# STM32H573 register map
File version: 1.8
CPU: CM33 r0p0, little endian, MPU, FPU, 4 interrupt priority bits
Registers are 32-bit, read-write, reset 0x0 unless marked. A register's access mark holds for its fields unless they carry their own. Offsets are from the block's base; [hi:lo] are bit positions; 'fields as' and 'values as' point back to an identical list.

## UCPD1 — USB Power Delivery interface
Base 0x4000DC00
Same registers: SEC_UCPD1 0x5000DC00
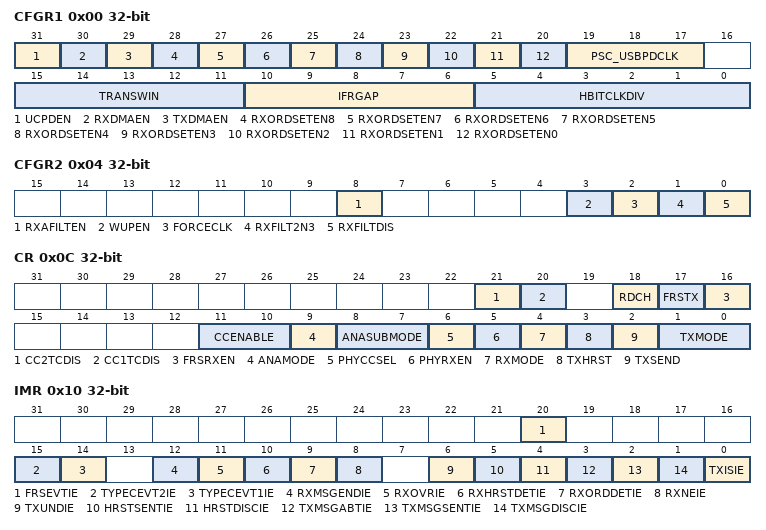
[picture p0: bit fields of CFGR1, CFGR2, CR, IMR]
0x00 CFGR1 access not given — UCPD configuration register 1
  [31] UCPDEN rw — UCPD peripheral enable General enable of the UCPD peripheral. Upon disabling, the peripheral instantly quits any ongoing activity and all control bits and bitfields default to their reset values. They must be set to their desired values each time the peripheral transits from disabled to enabled state.
    0=Disabled (UCPD peripheral disabled); 1=Enabled (UCPD peripheral enabled)
  [30] RXDMAEN rw — Reception DMA mode enable When set, the bit enables DMA mode for reception.
    0=Disabled (DMA mode for reception disabled); 1=Enabled (DMA mode for reception enabled)
  [29] TXDMAEN rw — Transmission DMA mode enable When set, the bit enables DMA mode for transmission.
    0=Disabled (DMA mode for transmission disabled); 1=Enabled (DMA mode for transmission enabled)
  [28] RXORDSETEN8 — SOP extension #2
    0=Disabled (Flag disabled); 1=Enabled (Flag enabled)
  [27] RXORDSETEN7 — SOP extension #1
    0=Disabled (Flag disabled); 1=Enabled (Flag enabled)
  [26] RXORDSETEN6 — SOP'' Debug
    0=Disabled (Flag disabled); 1=Enabled (Flag enabled)
  [25] RXORDSETEN5 — SOP'_Debug
    0=Disabled (Flag disabled); 1=Enabled (Flag enabled)
  [24] RXORDSETEN4 — Cable Detect reset
    0=Disabled (Flag disabled); 1=Enabled (Flag enabled)
  [23] RXORDSETEN3 — Hard Reset detection
    0=Disabled (Flag disabled); 1=Enabled (Flag enabled)
  [22] RXORDSETEN2 — SOP'' detection
    0=Disabled (Flag disabled); 1=Enabled (Flag enabled)
  [21] RXORDSETEN1 — SOP' detection
    0=Disabled (Flag disabled); 1=Enabled (Flag enabled)
  [20] RXORDSETEN0 — SOP detection
    0=Disabled (Flag disabled); 1=Enabled (Flag enabled)
  [19:17] PSC_USBPDCLK rw — Pre-scaler division ratio for generating ucpd_clk The bitfield determines the division ratio of a kernel clock pre-scaler producing UCPD peripheral clock (ucpd_clk). It is recommended to use the pre-scaler so as to set the ucpd_clk frequency in the range from 6 to 9 MHz.
    0=Div1 (Divide by 1); 1=Div2 (Divide by 2); 2=Div4 (Divide by 4); 3=Div8 (Divide by 8); 4=Div16 (Divide by 16)
  [15:11] TRANSWIN rw range 1..31 — Transition window duration The bitfield determines the division ratio (the bitfield value minus one) of a hbit_clk divider producing tTransitionWindow interval. Set a value that produces an interval of 12 to 20 us, taking into account the ucpd_clk frequency and the HBITCLKDIV[5:0] bitfield setting.
  [10:6] IFRGAP rw range 1..31 — Division ratio for producing inter-frame gap timer clock The bitfield determines the division ratio (the bitfield value minus one) of a ucpd_clk divider producing inter-frame gap timer clock (tInterFrameGap). The division ratio 15 is to apply for Tx clock at the USB PD 2.0 specification nominal value. The division ratios below 15 are to apply for Tx clock below nominal, and the division ratios above 15 for Tx clock above nominal.
  [5:0] HBITCLKDIV rw — Division ratio for producing half-bit clock The bitfield determines the division ratio (the bitfield value plus one) of a ucpd_clk divider producing half-bit clock (hbit_clk).
0x04 CFGR2 — UCPD configuration register 2
  [8] RXAFILTEN — Rx analog filter enable Setting the bit enables the Rx analog filter required for optimum Power Delivery reception.
    0=Disabled; 1=Enabled
  [3] WUPEN — Wakeup from Stop mode enable Setting the bit enables the UCPD_ASYNC_INT signal.
    0=Disabled; 1=Enabled
  [2] FORCECLK — Force ClkReq clock request
    0=NoForce (Do not force clock request); 1=Force clock request
  [1] RXFILT2N3 — BMC decoder Rx pre-filter sampling method Number of consistent consecutive samples before confirming a new value.
    0=Samp3 (3 samples); 1=Samp2 (2 samples)
  [0] RXFILTDIS — BMC decoder Rx pre-filter enable The sampling clock is that of the receiver (that is, after pre-scaler).
    0=Enabled (Rx pre-filter enabled); 1=Disabled (Rx pre-filter disabled)
0x0C CR — UCPD control register
  [21] CC2TCDIS — CC2 Type-C detector disable The bit disables the Type-C detector on the CC2 line. When enabled, the Type-C detector for CC2 is configured through ANAMODE and ANASUBMODE[1:0].
    0=Enabled (Type-C detector on the CCx line enabled); 1=Disabled (Type-C detector on the CCx line disabled)
  [20] CC1TCDIS — CC1 Type-C detector disable The bit disables the Type-C detector on the CC1 line. When enabled, the Type-C detector for CC1 is configured through ANAMODE and ANASUBMODE[1:0].
    values as CC2TCDIS
  [18] RDCH — Rdch condition drive The bit drives Rdch condition on the CC line selected through the PHYCCSEL bit (thus associated with VCONN), by remaining set during the source-only UnattachedWait.SRC state, to respect the Type-C state. Refer to 'USB Type-C ECN for Source VCONN Discharge'. The CCENABLE[1:0] bitfield must be set accordingly, too.
    0=NoEffect; 1=ConditionDrive (Rdch condition drive)
  [17] FRSTX — FRS Tx signaling enable. Setting the bit enables FRS Tx signaling. The bit is cleared by hardware after a delay respecting the USB Power Delivery specification Revision 3.0.
    0=NoEffect; 1=Enabled (FRS Tx signaling enabled)
  [16] FRSRXEN — FRS event detection enable Setting the bit enables FRS Rx event (FRSEVT) detection on the CC line selected through the PHYCCSEL bit. 0: Disable Clear the bit when the device is attached to an FRS-incapable source/sink.
    0=Disabled (FRS Rx event detection disabled); 1=Enabled (FRS Rx event detection enabled)
  [11:10] CCENABLE — CC line enable This bitfield enables CC1 and CC2 line analog PHYs (pull-ups and pull-downs) according to ANAMODE and ANASUBMODE[1:0] setting. A single line PHY can be enabled when, for example, the other line is driven by VCONN via an external VCONN switch. Enabling both PHYs is the normal usage for sink/source.
    0=Disabled (Both PHYs disabled); 1=CC1Enabled (CC1 PHY enabled); 2=CC2Enabled (CC2 PHY enabled); 3=BothEnabled (CC1 and CC2 PHYs enabled)
  [9] ANAMODE — Analog PHY operating mode The use of CC1 and CC2 depends on CCENABLE. Refer to ANAMODE, ANASUBMODE and link with TYPEC_VSTATE_CCx for the effect of this bitfield in conjunction with ANASUBMODE[1:0].
    0=Source; 1=Sink
  [8:7] ANASUBMODE — Analog PHY sub-mode Refer to TYPEC_VSTATE_CCx for the effect of this bitfield.
    0=Disabled; 1=Rp_DefaultUSB (Default USB Rp); 2=Rp_1_5A (1.5A Rp); 3=Rp_3A (3A Rp)
  [6] PHYCCSEL — CC1/CC2 line selector for USB Power Delivery signaling The selection depends on the cable orientation as discovered at attach.
    0=CC1 (Use CC1 IO for Power Delivery communication); 1=CC2 (Use CC2 IO for Power Delivery communication)
  [5] PHYRXEN — USB Power Delivery receiver enable Both CC1 and CC2 receivers are disabled when the bit is cleared. Only the CC receiver selected via the PHYCCSEL bit is enabled when the bit is set.
    0=Disabled (USB Power Delivery receiver disabled); 1=Enabled (USB Power Delivery receiver enabled)
  [4] RXMODE — Receiver mode Determines the mode of the receiver. When the bit is set, RXORDSET behaves normally, RXDR no longer receives bytes yet the CRC checking still proceeds as for a normal message. As this mode prevents reception of the header (containing MessageID), software has to auto-increment a received MessageID counter for inclusion in the GoodCRC acknowledge that must still be transmitted during this test.
    0=Normal receive mode; 1=BIST (BIST receive mode (BIST test data mode))
  [3] TXHRST — Command to send a Tx Hard Reset The bit is cleared by hardware as soon as the message transmission begins or is discarded.
    0=NoEffect; 1=Start Tx Hard Reset message
  [2] TXSEND — Command to send a Tx packet The bit is cleared by hardware as soon as the packet transmission begins or is discarded.
    0=NoEffect; 1=Start Tx packet transmission
  [1:0] TXMODE — Type of Tx packet Writing the bitfield triggers the action as follows, depending on the value: Others: invalid From V1.1 of the USB PD specification, there is a counter defined for the duration of the BIST Carrier Mode 2. To quit this mode correctly (after the 'tBISTContMode' delay), disable the peripheral (UCPDEN = 0).
    0=RegisterSet (Transmission of Tx packet previously defined in other registers); 1=Cable Reset sequence; 2=BIST test sequence (BIST Carrier Mode 2)
0x10 IMR access per field — UCPD interrupt mask register
  [all] fields
    0=Disabled (Interrupt disabled); 1=Enabled (Interrupt enabled)
  [20] FRSEVTIE ro — FRSEVT interrupt enable
  [15] TYPECEVT2IE rw — TYPECEVT2 interrupt enable
  [14] TYPECEVT1IE rw — TYPECEVT1 interrupt enable
  [12] RXMSGENDIE rw — RXMSGEND interrupt enable
  [11] RXOVRIE rw — RXOVR interrupt enable
  [10] RXHRSTDETIE rw — RXHRSTDET interrupt enable
  [9] RXORDDETIE rw — RXORDDET interrupt enable
  [8] RXNEIE rw — RXNE interrupt enable
  [6] TXUNDIE rw — TXUND interrupt enable
  [5] HRSTSENTIE rw — HRSTSENT interrupt enable
  [4] HRSTDISCIE rw — HRSTDISC interrupt enable
  [3] TXMSGABTIE rw — TXMSGABT interrupt enable
  [2] TXMSGSENTIE rw — TXMSGSENT interrupt enable
  [1] TXMSGDISCIE rw — TXMSGDISC interrupt enable
  [0] TXISIE rw — TXIS interrupt enable
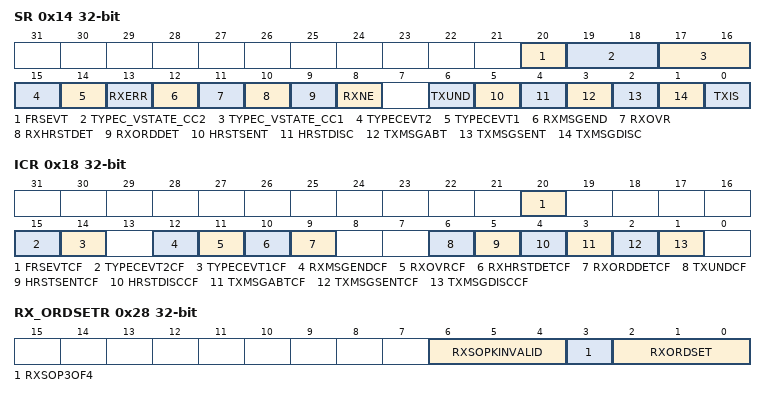
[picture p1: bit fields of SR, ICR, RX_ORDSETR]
0x14 SR ro — UCPD status register
  [20] FRSEVT — FRS detection event The flag is cleared by setting the FRSEVTCF bit.
    0=NoNewEvent; 1=NewEvent (New FRS receive event occurred)
  [19:18] TYPEC_VSTATE_CC2 — CC2 line voltage level The status bitfield indicates the voltage level on the CC2 line in its steady state. The voltage variation on the CC2 line during USB PD messages due to the BMC PHY modulation does not impact the bitfield value.
    0=Lowest; 1=Low; 2=High; 3=Highest
  [17:16] TYPEC_VSTATE_CC1 — The status bitfield indicates the voltage level on the CC1 line in its steady state. The voltage variation on the CC1 line during USB PD messages due to the BMC PHY modulation does not impact the bitfield value.
    0=Lowest; 1=Low; 2=High; 3=Highest
  [15] TYPECEVT2 — Type-C voltage level event on CC2 line The flag indicates a change of the TYPEC_VSTATE_CC2[1:0] bitfield value, which corresponds to a new Type-C event. It is cleared by setting the TYPECEVT2CF bit.
    0=NoNewEvent; 1=NewEvent (A new Type-C event occurred)
  [14] TYPECEVT1 — Type-C voltage level event on CC1 line The flag indicates a change of the TYPEC_VSTATE_CC1[1:0] bitfield value, which corresponds to a new Type-C event. It is cleared by setting the TYPECEVT2CF bit.
    0=NoNewEvent; 1=NewEvent (A new Type-C event occurred)
  [13] RXERR — Receive message error The flag indicates errors of the last Rx message declared (via RXMSGEND), such as incorrect CRC or truncated message (a line becoming static before EOP is met). It is asserted whenever the RXMSGEND flag is set.
    0=No error detected; 1=Error(s) detected
  [12] RXMSGEND — Rx message received The flag indicates whether a message (except Hard Reset message) has been received, regardless the CRC value. The flag is cleared by setting the RXMSGENDCF bit. The RXERR flag set when the RXMSGEND flag goes high indicates errors in the last-received message.
    0=NoNewMessage (No new Rx message received); 1=NewMessage (A new Rx message received)
  [11] RXOVR — Rx data overflow detection The flag indicates Rx data buffer overflow. It is cleared by setting the RXOVRCF bit. The buffer overflow can occur if the received data are not read fast enough.
    0=NoOverflow; 1=Overflow
  [10] RXHRSTDET — Rx Hard Reset receipt detection The flag indicates the receipt of valid Hard Reset message. It is cleared by setting the RXHRSTDETCF bit.
    0=NoHardReset (Hard Reset not received); 1=Hard Reset received
  [9] RXORDDET — Rx ordered set (4 K-codes) detection The flag indicates the detection of an ordered set. The relevant information is stored in the RXORDSET[2:0] bitfield of the UCPD_RX_ORDSET register. It is cleared by setting the RXORDDETCF bit.
    0=No ordered set detected; 1=Ordered set detected
  [8] RXNE — Receive data register not empty detection The flag indicates that the UCPD_RXDR register is not empty. It is automatically cleared upon reading UCPD_RXDR.
    0=Empty (Rx data register empty); 1=NotEmpty (Rx data register not empty)
  [6] TXUND — Tx data underrun detection The flag indicates that the Tx data register (UCPD_TXDR) was not written in time for a transmit message to execute normally. It is cleared by setting the TXUNDCF bit.
    0=NoUnderrun (No Tx data underrun detected); 1=Underrun (Tx data underrun detected)
  [5] HRSTSENT — Hard Reset message sent The flag indicates that the Hard Reset message is sent. The flag is cleared by setting the HRSTSENTCF bit.
    0=NotSent (No Hard Reset message sent); 1=Sent (Hard Reset message sent)
  [4] HRSTDISC — Hard Reset discarded The flag indicates that the Hard Reset message is discarded. The flag is cleared by setting the HRSTDISCCF bit.
    0=NotDiscarded (No Hard Reset discarded); 1=Discarded (Hard Reset discarded)
  [3] TXMSGABT — Transmit message abort The flag indicates that a Tx message is aborted due to a subsequent Hard Reset message send request taking priority during transmit. It is cleared by setting the TXMSGABTCF bit.
    0=NoAbort (No transmit message abort); 1=Abort (Transmit message abort)
  [2] TXMSGSENT — Message transmission completed The flag indicates the completion of packet transmission. It is cleared by setting the TXMSGSENTCF bit. In the event of a message transmission interrupted by a Hard Reset, the flag is not raised.
    0=NotCompleted (No Tx message completed); 1=Completed (Tx message completed)
  [1] TXMSGDISC — Message transmission discarded The flag indicates that a message transmission was dropped. The flag is cleared by setting the TXMSGDISCCF bit. Transmission of a message can be dropped if there is a concurrent receive in progress or at excessive noise on the line. After a Tx message is discarded, the flag is only raised when the CC line becomes idle.
    0=NotDiscarded (No Tx message discarded); 1=Discarded (Tx message discarded)
  [0] TXIS — Transmit interrupt status The flag indicates that the UCPD_TXDR register is empty and new data write is required (as the amount of data sent has not reached the payload size defined in the TXPAYSZ bitfield). The flag is cleared with the data write into the UCPD_TXDR register.
    0=NotRequired (New Tx data write not required); 1=Required (New Tx data write required)
0x18 ICR wo — UCPD interrupt clear register
  [all] fields
    1=Clear flag in UCPD_SR
  [20] FRSEVTCF — FRS event flag (FRSEVT) clear Setting the bit clears the FRSEVT flag in the UCPD_SR register.
  [15] TYPECEVT2CF — Type-C CC2 line event flag (TYPECEVT2) clear Setting the bit clears the TYPECEVT2 flag in the UCPD_SR register
  [14] TYPECEVT1CF — Type-C CC1 event flag (TYPECEVT1) clear Setting the bit clears the TYPECEVT1 flag in the UCPD_SR register
  [12] RXMSGENDCF — Rx message received flag (RXMSGEND) clear Setting the bit clears the RXMSGEND flag in the UCPD_SR register.
  [11] RXOVRCF — Rx overflow flag (RXOVR) clear Setting the bit clears the RXOVR flag in the UCPD_SR register.
  [10] RXHRSTDETCF — Rx Hard Reset detect flag (RXHRSTDET) clear Setting the bit clears the RXHRSTDET flag in the UCPD_SR register.
  [9] RXORDDETCF — Rx ordered set detect flag (RXORDDET) clear Setting the bit clears the RXORDDET flag in the UCPD_SR register.
  [6] TXUNDCF — Tx underflow flag (TXUND) clear Setting the bit clears the TXUND flag in the UCPD_SR register.
  [5] HRSTSENTCF — Hard reset send flag (HRSTSENT) clear Setting the bit clears the HRSTSENT flag in the UCPD_SR register.
  [4] HRSTDISCCF — Hard reset discard flag (HRSTDISC) clear Setting the bit clears the HRSTDISC flag in the UCPD_SR register.
  [3] TXMSGABTCF — Tx message abort flag (TXMSGABT) clear Setting the bit clears the TXMSGABT flag in the UCPD_SR register.
  [2] TXMSGSENTCF — Tx message send flag (TXMSGSENT) clear Setting the bit clears the TXMSGSENT flag in the UCPD_SR register.
  [1] TXMSGDISCCF — Tx message discard flag (TXMSGDISC) clear Setting the bit clears the TXMSGDISC flag in the UCPD_SR register.
0x1C TX_ORDSETR — UCPD Tx ordered set type register
  [19:0] TXORDSET — Ordered set to transmit The bitfield determines a full 20-bit sequence to transmit, consisting of four K-codes, each of five bits, defining the packet to transmit. The bit 0 (bit 0 of K-code1) is the first, the bit 19 (bit 4 of K code4) the last.
0x20 TX_PAYSZR — UCPD Tx payload size register
  [9:0] TXPAYSZ — Payload size yet to transmit The bitfield is modified by software and by hardware. It contains the number of bytes of a payload (including header but excluding CRC) yet to transmit: each time a data byte is written into the UCPD_TXDR register, the bitfield value decrements and the TXIS bit is set, except when the bitfield value reaches zero. The enumerated values are standard payload sizes before the start of transmission.
0x24 TXDR — UCPD Tx data register
  [7:0] TXDATA — Data byte to transmit
0x28 RX_ORDSETR ro — UCPD Rx ordered set register
  [6:4] RXSOPKINVALID — The bitfield is for debug purposes only. Others: Invalid
    0=Valid (No K-code corrupted); 1=FirstCorrupted (First K-code corrupted); 2=SecondCorrupted (Second K-code corrupted); 3=ThirdCorrupted (Third K-code corrupted); 4=FourthCorrupted (Fourth K-code corrupted)
  [3] RXSOP3OF4 — The bit indicates the number of correct K codes. For debug purposes only.
    0=AllCorrect (4 correct K-codes out of 4); 1=OneIncorrect (3 correct K-codes out of 4)
  [2:0] RXORDSET — Rx ordered set code detected
    0=SOP (SOP code detected in receiver); 1=SOPPrime (SOP' code detected in receiver); 2=SOPDoublePrime (SOP'' code detected in receiver); 3=SOPPrimeDebug (SOP'_Debug detected in receiver); 4=SOPDoublePrimeDebug (SOP''_Debug detected in receiver); 5=Cable Reset detected in receiver; 6=SOP extension #1 detected in receiver; 7=SOP extension #2 detected in receiver
0x2C RX_PAYSZR ro — UCPD Rx payload size register
  [9:0] RXPAYSZ — Rx payload size received This bitfield contains the number of bytes of a payload (including header but excluding CRC) received: each time a new data byte is received in the UCPD_RXDR register, the bitfield value increments and the RXMSGEND flag is set (and an interrupt generated if enabled). The bitfield may return a spurious value when a byte reception is ongoing (the RXMSGEND flag is low).
0x30 RXDR ro — UCPD receive data register
  [7:0] RXDATA — Data byte received
0x34 RX_ORDEXTR1 — UCPD Rx ordered set extension register 1
  [19:0] RXSOPX1 — Ordered set 1 received The bitfield contains a full 20-bit sequence received, consisting of four K codes, each of five bits. The bit 0 (bit 0 of K code1) is receive first, the bit 19 (bit 4 of K code4) last.
0x38 RX_ORDEXTR2 — UCPD Rx ordered set extension register 2
  [19:0] RXSOPX2 — Ordered set 2 received The bitfield contains a full 20-bit sequence received, consisting of four K codes, each of five bits. The bit 0 (bit 0 of K code1) is receive first, the bit 19 (bit 4 of K code4) last.
